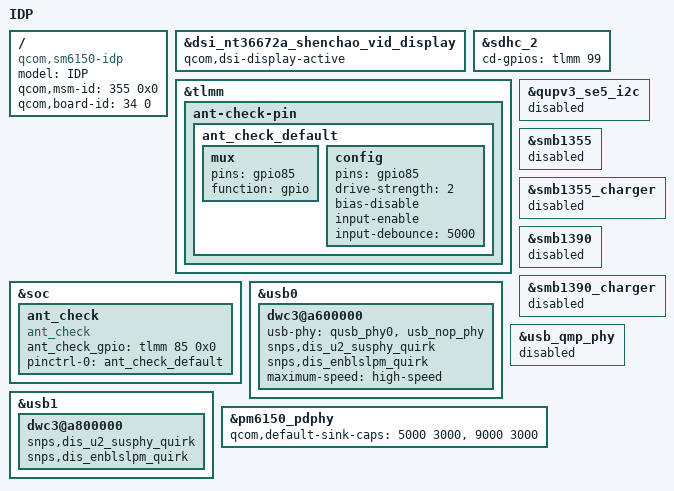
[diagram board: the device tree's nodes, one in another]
/* Copyright (c) 2018, The Linux Foundation. All rights reserved.
 *
 * This program is free software; you can redistribute it and/or modify
 * it under the terms of the GNU General Public License version 2 and
 * only version 2 as published by the Free Software Foundation.
 *
 * This program is distributed in the hope that it will be useful,
 * but WITHOUT ANY WARRANTY; without even the implied warranty of
 * MERCHANTABILITY or FITNESS FOR A PARTICULAR PURPOSE.  See the
 * GNU General Public License for more details.
 */

/dts-v1/;
/plugin/;

#include <dt-bindings/interrupt-controller/arm-gic.h>
#include <dt-bindings/clock/qcom,camcc-sm6150.h>

#include "sm6150-idp.dtsi"
#include "sm6150-audio-overlay.dtsi"

/ {
	model = "IDP";
	compatible = "qcom,sm6150-idp", "qcom,sm6150", "qcom,idp";
	qcom,msm-id = <355 0x0>;
	qcom,board-id = <34 0>;
};

&dsi_nt36672a_shenchao_vid_display {
	qcom,dsi-display-active;
};

&sdhc_2 {
	cd-gpios = <&tlmm 99 0>;
};

&tlmm {
	ant-check-pin {
		ant_check_default: ant_check_default {
			mux {
				pins = "gpio85";
				function = "gpio";
			};
			config {
				pins = "gpio85";
				drive-strength = <2>;
				bias-disable;
				input-enable;
				input-debounce = <5000>;
			};
		};
	};
};

&soc {
	ant_check {
		compatible = "ant_check";
	        ant_check_gpio = <&tlmm 85 0x0>;
		pinctrl-names = "default";
		pinctrl-0 = <&ant_check_default>;
	};
};

&qupv3_se5_i2c {
	status = "disabled";
};

&smb1355 {
	status = "disabled";
};

&smb1355_charger {
	status = "disabled";
};

&smb1390 {
	status = "disabled";
};

&smb1390_charger {
	status = "disabled";
};

&usb0{
	dwc3@a600000 {
		usb-phy = <&qusb_phy0>, <&usb_nop_phy>;
		snps,dis_u2_susphy_quirk;
		snps,dis_enblslpm_quirk;
		maximum-speed = "high-speed";
	};
};

&usb_qmp_phy {
	status = "disabled";
};

&usb1{
	dwc3@a800000 {
		snps,dis_u2_susphy_quirk;
		snps,dis_enblslpm_quirk;
	};
};

&pm6150_pdphy{
	qcom,default-sink-caps = <5000 3000>, /* 5V @ 3A */
						 <9000 3000>; /* 9V @ 3A */
};
